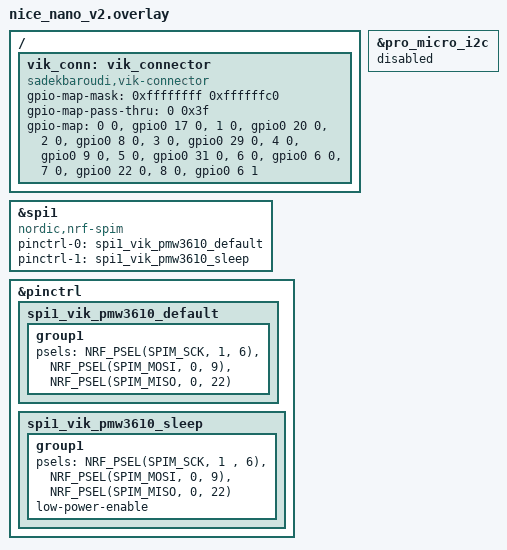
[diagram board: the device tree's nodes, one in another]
/*
 * Copyright (c) 2022 The ZMK Contributors
 *
 * SPDX-License-Identifier: MIT
 */

 ///////// VIK SPI and connector start
&spi1 {
    compatible = "nordic,nrf-spim";
    pinctrl-0 = <&spi1_vik_pmw3610_default>;
    pinctrl-1 = <&spi1_vik_pmw3610_sleep>;
    pinctrl-names = "default", "sleep";
};

/ {
	vik_conn: vik_connector {
		compatible = "sadekbaroudi,vik-connector";
		#gpio-cells = <2>;
		gpio-map-mask = <0xffffffff 0xffffffc0>;
		gpio-map-pass-thru = <0 0x3f>;
		gpio-map
			= <0 0 &gpio0  17 0>    /* vik SDA */
			, <1 0 &gpio0  20 0>    /* vik SCL */
			, <2 0 &gpio0   8 0>    /* vik RGB Data */
			, <3 0 &gpio0  29 0>    /* vik AD_1 */
			, <4 0 &gpio0   9 0>    /* vik MOSI */
			, <5 0 &gpio0  31 0>    /* vik AD_2 */
			, <6 0 &gpio0   6 0>    /* vik CS */
			, <7 0 &gpio0  22 0>    /* vik MISO */
			, <8 0 &gpio0   6 1>    /* vik SCLK */
			;
	};
};

vik_spi_pmw3610: &spi1 {};
///////// VIK SPI and connector end

&pinctrl {
    // VIK SPI pinctrl start
    spi1_vik_pmw3610_default: spi1_vik_pmw3610_default  {
        group1 {
            psels = <NRF_PSEL(SPIM_SCK, 1, 6)>,
                <NRF_PSEL(SPIM_MOSI, 0, 9)>,
                <NRF_PSEL(SPIM_MISO, 0, 22)>;
        };
    };
    spi1_vik_pmw3610_sleep: spi1_vik_pmw3610_sleep  {
        group1 {
            psels = <NRF_PSEL(SPIM_SCK, 1 , 6)>,
                <NRF_PSEL(SPIM_MOSI, 0, 9)>,
                <NRF_PSEL(SPIM_MISO, 0, 22)>;
            low-power-enable;
        };
    };
};

&pro_micro_i2c {
    status = "disabled";
};
